# ESP32-S31 register map
Vendor: ESPRESSIF SYSTEMS (SHANGHAI) CO., LTD.; Series: ESP32 S-Series; File version: 1
CPU: RV32IMAFC r0p0, little endian, no MPU, FPU, 0 interrupt priority bits
Address unit: 32 bits
Registers are 32-bit, read-write, reset 0x0 unless marked. A register's access mark holds for its fields unless they carry their own. Offsets are from the block's base; [hi:lo] are bit positions; {n}, {i} and the like mark numbered series.

## CLINT — Core Local Interrupts
Base 0x10000000
Same registers: CLINT_OTHER_CORE 0x10010000
0x00 MSIP — Core-local machine software interrupt pending register
  [0] MSIP — Configures the pending status of the machine software interrupt.
0x4000 MTIMECMP 64-bit (reset mask 0xFFFFFFFF) — Core-local machine timer compare value
  [63:0] MTIMECMP — Represents the value to compare with the system counter.
0x4008 MTIMELOAD 64-bit (reset mask 0xFFFFFFFF) — Core-local machine timer load value
  [63:0] MTIMELOAD — Represents the value to be loaded to the system counter.
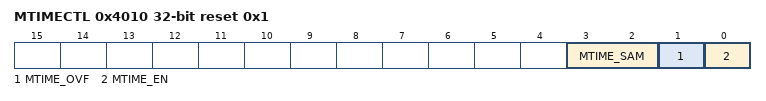
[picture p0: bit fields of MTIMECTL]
0x4010 MTIMECTL reset 0x1 — Core-local machine timer interrupt control/status register
  [3:2] MTIME_SAM — Configures the sampling mode of MTIME, to allow reading the 64-bit counter value consistently.
    0=NONE (No sampling); 1=SAMPLE_HIGH (Sample the upper half of the system counter when the lower half of MTIME is read); 2=SAMPLE_LOW (Sample the lower half of the system counter when the upper half of MTIME is read); 3=SAMPLE_OTHER (Sample the other half of the system counter when either half of MTIME is read)
  [1] MTIME_OVF — Set by hardware when the system counter reaches its maximum value. Software can clear this bit by writing 0 to it.
  [0] MTIME_EN — Configures whether to enable the system counter. This bit is implemented in the CLINT of core 0 only.
0xBFF8 MTIME 64-bit ro (reset mask 0xFFFFFFFF) — Core-local system counter value
  [63:0] MTIME — Represents the current value of the system counter.

## CLIC — Core Local Interrupt Controller
Base 0x10800000
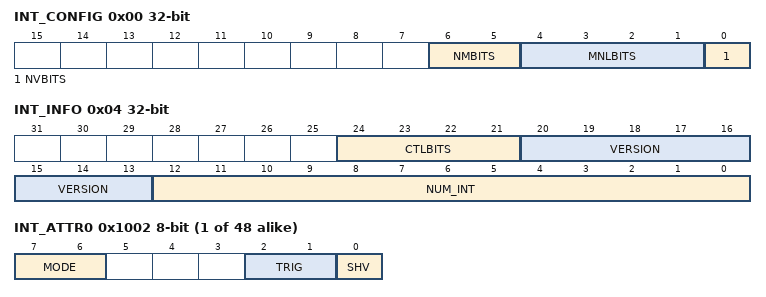
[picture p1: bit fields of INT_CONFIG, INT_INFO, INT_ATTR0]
0x00 INT_CONFIG access per field
  [6:5] NMBITS ro — The effective number of bits in the privileged state.
  [4:1] MNLBITS rw — Machine mode interrupt priority effective digits, the maximum value is 8.
  [0] NVBITS ro — Hardware vector interrupt implementation flag bit.
0x04 INT_INFO ro
  [24:21] CTLBITS — The effective bits of priority in the CLICINTCTL register.
  [20:13] VERSION — The lower 4 bits are the modified version of the hardware implementation; the upper 4 bits are the CLIC architecture version information.
  [12:0] NUM_INT — The number of interrupt sources.
0x08 INT_THRESH
  [31:24] CPU_INT_THRESH — Threshold for machine mode interruption.
{0x1000+4i} INT_IP{i} (i=0..47) 8-bit — Interrupt pending register.
  [0] INT_IP — Interrupt pending bit.
{0x1001+4i} INT_IE{i} (i=0..47) 8-bit — Interrupt enable register.
  [0] INT_IE — Interrupt enable bit.
{0x1002+4i} INT_ATTR{i} (i=0..47) 8-bit access per field — Interrupt attribute register.
  [7:6] MODE ro — Privilege mode of the interrupt, hardwired to 0x3 (machine mode).
  [2:1] TRIG rw — Configures the trigger type and polarity of the interrupt.
    0=POSITIVE_LEVEL (interrupt is positive level-triggered); 1=POSITIVE_EDGE (interrupt is positive edge-triggered); 2=NEGATIVE_LEVEL (interrupt is negative level-triggered); 3=NEGATIVE_EDGE (interrupt is negative edge-triggered)
  [0] SHV rw — Represents whether the interrupt is a hardware vector interrupt.
    0=SOFTWARE (Not hardware vectored. Upon taking this interrupt, the CPU will jump to the address configured in mtvec.); 1=HARDWARE (Hardware vectored. Upon taking this interrupt, the CPU will jump to the word address stored at (mtvt + 4*i) relative to the base address configured in mtvt.)
{0x1003+4i} INT_CTL{i} (i=0..47) 8-bit access per field — Interrupt level control register.
  [7:5] CTL rw — Configures the level and priority of the interrupt.

## MODEM_SYSCON
Base 0x20109C00
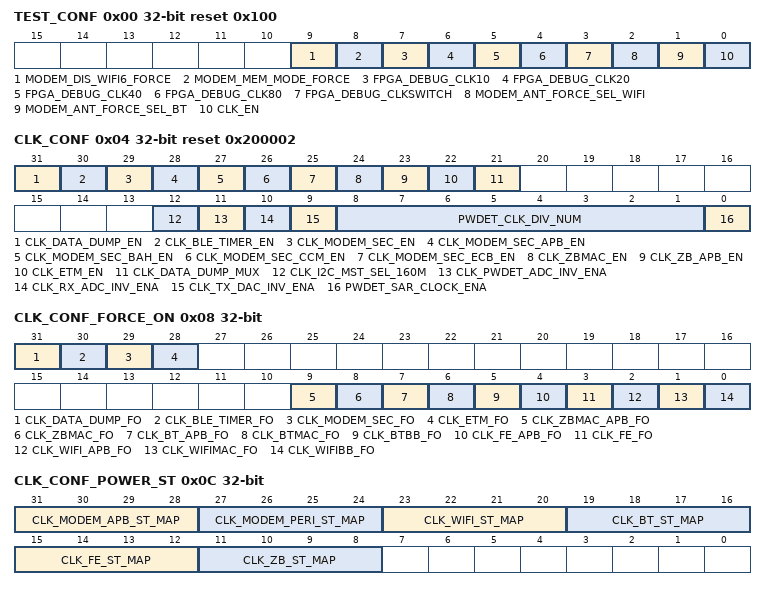
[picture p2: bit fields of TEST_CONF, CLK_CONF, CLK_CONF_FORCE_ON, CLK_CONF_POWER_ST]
0x00 TEST_CONF reset 0x100
  [9] MODEM_DIS_WIFI6_FORCE, [8] MODEM_MEM_MODE_FORCE, [7] FPGA_DEBUG_CLK10, [6] FPGA_DEBUG_CLK20, [5] FPGA_DEBUG_CLK40, [4] FPGA_DEBUG_CLK80, [3] FPGA_DEBUG_CLKSWITCH, [2] MODEM_ANT_FORCE_SEL_WIFI, [1] MODEM_ANT_FORCE_SEL_BT, [0] CLK_EN
0x04 CLK_CONF reset 0x200002
  [31] CLK_DATA_DUMP_EN, [30] CLK_BLE_TIMER_EN, [29] CLK_MODEM_SEC_EN, [28] CLK_MODEM_SEC_APB_EN, [27] CLK_MODEM_SEC_BAH_EN, [26] CLK_MODEM_SEC_CCM_EN, [25] CLK_MODEM_SEC_ECB_EN, [24] CLK_ZBMAC_EN, [23] CLK_ZB_APB_EN, [22] CLK_ETM_EN, [21] CLK_DATA_DUMP_MUX, [12] CLK_I2C_MST_SEL_160M, [11] CLK_PWDET_ADC_INV_ENA, [10] CLK_RX_ADC_INV_ENA, [9] CLK_TX_DAC_INV_ENA, [8:1] PWDET_CLK_DIV_NUM, [0] PWDET_SAR_CLOCK_ENA
0x08 CLK_CONF_FORCE_ON
  [31] CLK_DATA_DUMP_FO, [30] CLK_BLE_TIMER_FO, [29] CLK_MODEM_SEC_FO, [28] CLK_ETM_FO, [9] CLK_ZBMAC_APB_FO, [8] CLK_ZBMAC_FO, [7] CLK_BT_APB_FO, [6] CLK_BTMAC_FO, [5] CLK_BTBB_FO, [4] CLK_FE_APB_FO, [3] CLK_FE_FO, [2] CLK_WIFI_APB_FO, [1] CLK_WIFIMAC_FO, [0] CLK_WIFIBB_FO
0x0C CLK_CONF_POWER_ST
  [31:28] CLK_MODEM_APB_ST_MAP, [27:24] CLK_MODEM_PERI_ST_MAP, [23:20] CLK_WIFI_ST_MAP, [19:16] CLK_BT_ST_MAP, [15:12] CLK_FE_ST_MAP, [11:8] CLK_ZB_ST_MAP
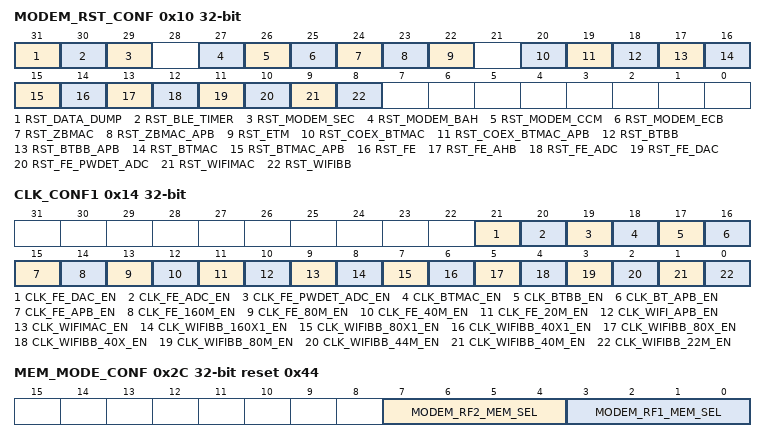
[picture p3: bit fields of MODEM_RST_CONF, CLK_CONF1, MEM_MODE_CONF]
0x10 MODEM_RST_CONF
  [31] RST_DATA_DUMP, [30] RST_BLE_TIMER, [29] RST_MODEM_SEC, [27] RST_MODEM_BAH, [26] RST_MODEM_CCM, [25] RST_MODEM_ECB, [24] RST_ZBMAC, [23] RST_ZBMAC_APB, [22] RST_ETM, [20] RST_COEX_BTMAC, [19] RST_COEX_BTMAC_APB, [18] RST_BTBB, [17] RST_BTBB_APB, [16] RST_BTMAC, [15] RST_BTMAC_APB, [14] RST_FE, [13] RST_FE_AHB, [12] RST_FE_ADC, [11] RST_FE_DAC, [10] RST_FE_PWDET_ADC, [9] RST_WIFIMAC, [8] RST_WIFIBB
0x14 CLK_CONF1
  [21] CLK_FE_DAC_EN, [20] CLK_FE_ADC_EN, [19] CLK_FE_PWDET_ADC_EN, [18] CLK_BTMAC_EN, [17] CLK_BTBB_EN, [16] CLK_BT_APB_EN, [15] CLK_FE_APB_EN, [14] CLK_FE_160M_EN, [13] CLK_FE_80M_EN, [12] CLK_FE_40M_EN, [11] CLK_FE_20M_EN, [10] CLK_WIFI_APB_EN, [9] CLK_WIFIMAC_EN, [8] CLK_WIFIBB_160X1_EN, [7] CLK_WIFIBB_80X1_EN, [6] CLK_WIFIBB_40X1_EN, [5] CLK_WIFIBB_80X_EN, [4] CLK_WIFIBB_40X_EN, [3] CLK_WIFIBB_80M_EN, [2] CLK_WIFIBB_44M_EN, [1] CLK_WIFIBB_40M_EN, [0] CLK_WIFIBB_22M_EN
0x18 WIFI_BB_CFG
0x1C FE_CFG
0x20 MEM_RF1_CONF reset 0x2070
  [31:0] MODEM_RF1_MEM_AUX_CTRL
0x24 MEM_RF2_CONF
  [31:0] MODEM_RF2_MEM_AUX_CTRL
0x28 BTMAC_CLK_CFG
  [0] CLK_BTMAC_LOW_RATE
0x2C MEM_MODE_CONF reset 0x44
  [7:4] MODEM_RF2_MEM_SEL, [3:0] MODEM_RF1_MEM_SEL
0x30 DATE reset 0x2508080
  [27:0] DATE
